# ATSAM4E16CB register map
Vendor: Atmel; Series: SAM4E; File version: 0
CPU: CM4 r0p1, selectable endian, MPU, FPU, 4 interrupt priority bits
Registers are 32-bit, read-write, reset 0x0 unless marked. A register's access mark holds for its fields unless they carry their own. Offsets are from the block's base; [hi:lo] are bit positions; {n}, {i} and the like mark numbered series.

## EFC — Embedded Flash Controller
Base 0x400E0A00; register names take the prefix EFC_
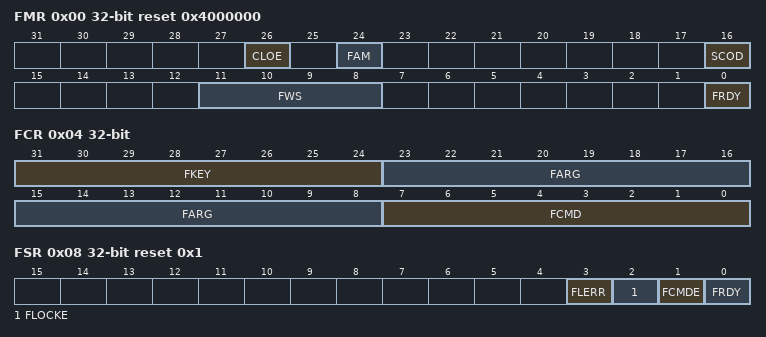
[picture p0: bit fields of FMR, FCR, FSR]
0x00 FMR reset 0x4000000 — EEFC Flash Mode Register
  [26] CLOE — Code Loop Optimization Enable
  [24] FAM — Flash Access Mode
  [16] SCOD — Sequential Code Optimization Disable
  [11:8] FWS — Flash Wait State
  [0] FRDY — Ready Interrupt Enable
0x04 FCR wo reset not defined — EEFC Flash Command Register
  [31:24] FKEY — Flash Writing Protection Key
    90=PASSWD (The 0x5A value enables the command defined by the bits of the register. If the field is written with a different value, the write is not performed and no action is started.)
  [23:8] FARG — Flash Command Argument
  [7:0] FCMD — Flash Command
    0=GETD (Get Flash descriptor); 1=WP (Write page); 2=WPL (Write page and lock); 3=EWP (Erase page and write page); 4=EWPL (Erase page and write page then lock); 5=EA (Erase all); 7=EPA (Erase pages); 8=SLB (Set lock bit); 9=CLB (Clear lock bit); 10=GLB (Get lock bit); 11=SGPB (Set GPNVM bit); 12=CGPB (Clear GPNVM bit); 13=GGPB (Get GPNVM bit); 14=STUI (Start read unique identifier); 15=SPUI (Stop read unique identifier); 16=GCALB (Get CALIB bit); 17=ES (Erase sector); 18=WUS (Write user signature); 19=EUS (Erase user signature); 20=STUS (Start read user signature); 21=SPUS (Stop read user signature)
0x08 FSR ro reset 0x1 — EEFC Flash Status Register
  [3] FLERR — Flash Error Status
  [2] FLOCKE — Flash Lock Error Status
  [1] FCMDE — Flash Command Error Status
  [0] FRDY — Flash Ready Status
0x0C FRR ro — EEFC Flash Result Register
  [31:0] FVALUE — Flash Result Value

## RSTC — Reset Controller
Base 0x400E1800; register names take the prefix RSTC_
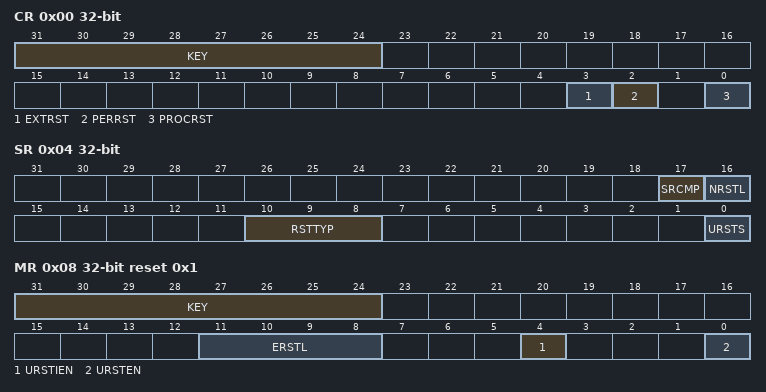
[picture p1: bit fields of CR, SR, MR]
0x00 CR wo reset not defined — Control Register
  [31:24] KEY — System Reset Key
    165=PASSWD (Writing any other value in this field aborts the write operation.)
  [3] EXTRST — External Reset
  [2] PERRST — Peripheral Reset
  [0] PROCRST — Processor Reset
0x04 SR ro — Status Register
  [17] SRCMP — Software Reset Command in Progress
  [16] NRSTL — NRST Pin Level
  [10:8] RSTTYP — Reset Type
    0=GENERAL_RST (First power-up reset); 1=BACKUP_RST (Return from Backup Mode); 2=WDT_RST (Watchdog fault occurred); 3=SOFT_RST (Processor reset required by the software); 4=USER_RST (NRST pin detected low)
  [0] URSTS — User Reset Status
0x08 MR reset 0x1 — Mode Register
  [31:24] KEY — Write Access Password
    165=PASSWD (Writing any other value in this field aborts the write operation.Always reads as 0.)
  [11:8] ERSTL — External Reset Length
  [4] URSTIEN — User Reset Interrupt Enable
  [0] URSTEN — User Reset Enable

## RTT — Real-time Timer
Base 0x400E1830; register names take the prefix RTT_
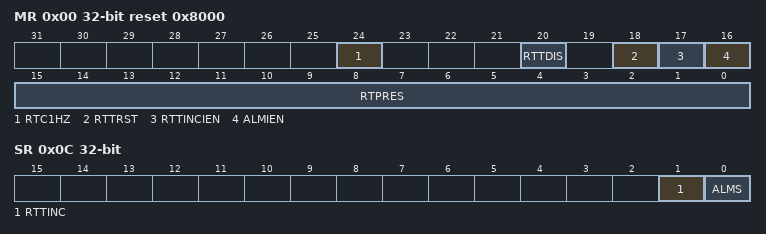
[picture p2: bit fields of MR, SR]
0x00 MR reset 0x8000 — Mode Register
  [24] RTC1HZ — Real-Time Clock 1Hz Clock Selection
  [20] RTTDIS — Real-time Timer Disable
  [18] RTTRST — Real-time Timer Restart
  [17] RTTINCIEN — Real-time Timer Increment Interrupt Enable
  [16] ALMIEN — Alarm Interrupt Enable
  [15:0] RTPRES — Real-time Timer Prescaler Value
0x04 AR reset 0xFFFFFFFF — Alarm Register
  [31:0] ALMV — Alarm Value
0x08 VR ro — Value Register
  [31:0] CRTV — Current Real-time Value
0x0C SR ro — Status Register
  [1] RTTINC — Prescaler Roll-over Status
  [0] ALMS — Real-time Alarm Status

## WDT — Watchdog Timer
Base 0x400E1850; register names take the prefix WDT_
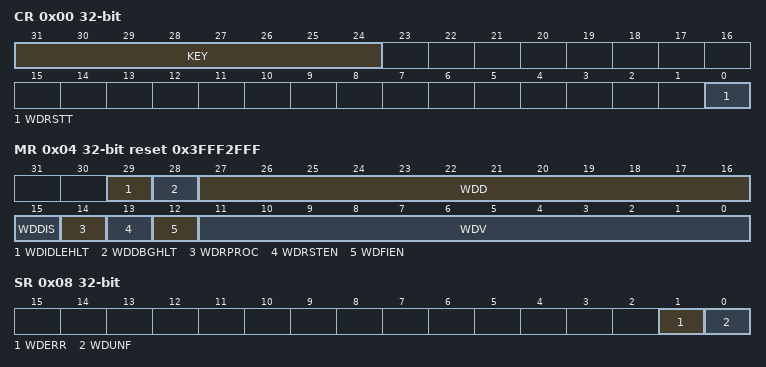
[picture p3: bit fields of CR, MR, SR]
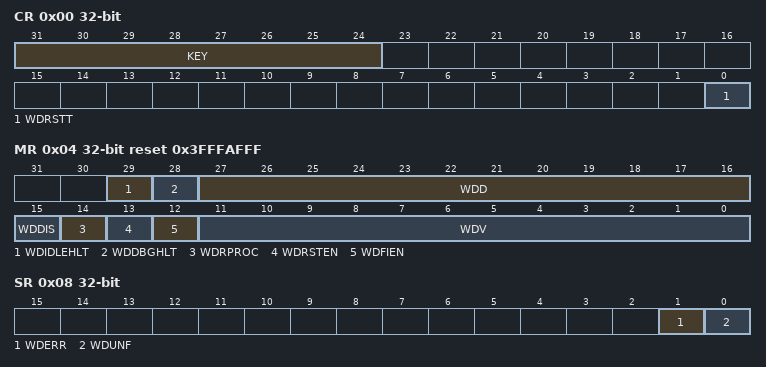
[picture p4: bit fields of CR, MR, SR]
0x00 CR wo reset not defined — Control Register
  [31:24] KEY — Password.
    165=PASSWD (Writing any other value in this field aborts the write operation.)
  [0] WDRSTT — Watchdog Restart
0x04 MR reset 0x3FFF2FFF — Mode Register
  [29] WDIDLEHLT — Watchdog Idle Halt
  [28] WDDBGHLT — Watchdog Debug Halt
  [27:16] WDD — Watchdog Delta Value
  [15] WDDIS — Watchdog Disable
  [14] WDRPROC — Watchdog Reset Processor
  [13] WDRSTEN — Watchdog Reset Enable
  [12] WDFIEN — Watchdog Fault Interrupt Enable
  [11:0] WDV — Watchdog Counter Value
0x08 SR ro — Status Register
  [1] WDERR — Watchdog Error
  [0] WDUNF — Watchdog Underflow

## GPBR — General Purpose Backup Registers
Base 0x400E1890; register names take the prefix GPBR_
{0x0+4i} GPBR[{i}] (i=0..19) reset not defined — General Purpose Backup Register
  [31:0] GPBR_VALUE — Value of GPBR x

## RSWDT — Reinforced Safety Watchdog Timer
Base 0x400E1900; register names take the prefix RSWDT_
0x00 CR wo reset not defined — Control Register
  [31:24] KEY — Password
    196=PASSWD (Writing any other value in this field aborts the write operation.)
  [0] WDRSTT — Watchdog Restart
0x04 MR reset 0x3FFFAFFF — Mode Register
  [29] WDIDLEHLT — Watchdog Idle Halt
  [28] WDDBGHLT — Watchdog Debug Halt
  [27:16] WDD — Watchdog Delta Value
  [15] WDDIS — Watchdog Disable
  [14] WDRPROC — Watchdog Reset Processor
  [13] WDRSTEN — Watchdog Reset Enable
  [12] WDFIEN — Watchdog Fault Interrupt Enable
  [11:0] WDV — Watchdog Counter Value
0x08 SR ro — Status Register
  [1] WDERR — Watchdog Error
  [0] WDUNF — Watchdog Underflow
